AUTOSAR XML (schema 00052)
package /katech/AdaptiveApplicationSwComponentTypes
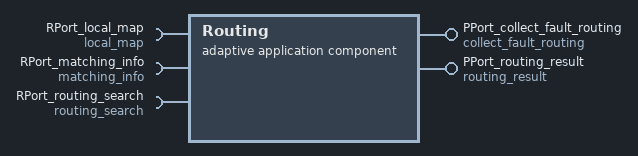
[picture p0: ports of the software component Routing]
  adaptive application sw component type Routing
    provide port PPort_collect_fault_routing: provided-interface=collect_fault_routing
    provide port PPort_routing_result: provided-interface=routing_result
    require port RPort_local_map: required-interface=local_map
    require port RPort_matching_info: required-interface=matching_info
    require port RPort_routing_search: required-interface=routing_search
package /katech/Executables
  executable Routing: category=APPLICATION_LEVEL, minimum-timer-granularity=1000
    root sw component prototype Routing: application-type=Routing
